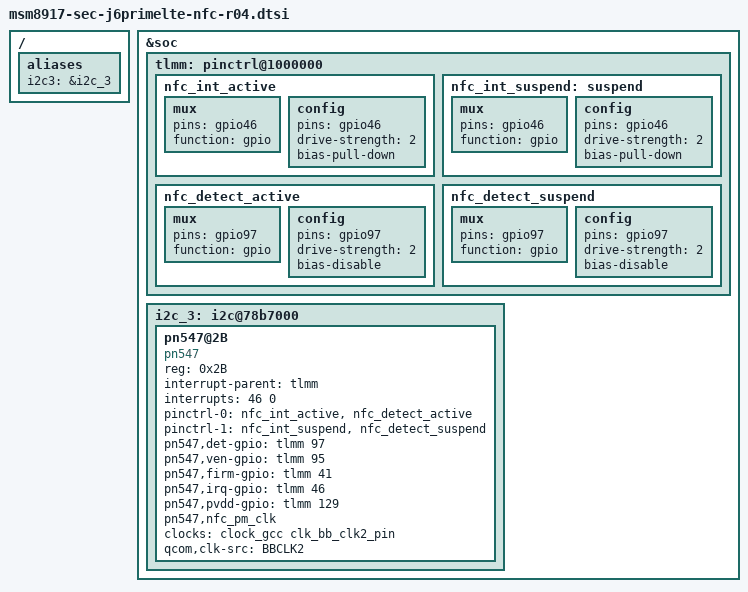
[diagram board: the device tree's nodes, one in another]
/* Copyright (c) 2017-2018, The Linux Foundation. All rights reserved.
 *
 * This program is free software; you can redistribute it and/or modify
 * it under the terms of the GNU General Public License version 2 and
 * only version 2 as published by the Free Software Foundation.
 *
 * This program is distributed in the hope that it will be useful,
 * but WITHOUT ANY WARRANTY; without even the implied warranty of
 * MERCHANTABILITY or FITNESS FOR A PARTICULAR PURPOSE.  See the
 * GNU General Public License for more details.
 */
/ {
	aliases {
		i2c3 = &i2c_3;
	};
};

&soc {
	tlmm: pinctrl@1000000 {
		/delete-node/ pmx_rd_nfc_int;

		nfc_int_active: nfc_int_active {
			mux {
				pins = "gpio46";
				function = "gpio";
			};
			config {
				pins = "gpio46";
				drive-strength = <2>;
				bias-pull-down;
			};
		};
		nfc_int_suspend: suspend  {
			mux {
				pins = "gpio46";
				function = "gpio";
			};
			config {
				pins = "gpio46";
				drive-strength = <2>;
				bias-pull-down;
			};
		};

		nfc_detect_active: nfc_detect_active {
			mux {
				pins = "gpio97";
				function = "gpio";
			};
			config {
				pins = "gpio97";
				drive-strength = <2>;
				bias-disable;		/* No PULL */
			};
		};
		nfc_detect_suspend: nfc_detect_suspend {
			mux {
				pins = "gpio97";
				function = "gpio";
			};
			config {
				pins = "gpio97";
				drive-strength = <2>;
				bias-disable;		/* No PULL */
			};
		};
	};

	i2c_3: i2c@78b7000 { /* BLSP1 QUP3 */
/*
		compatible = "qcom,i2c-msm-v2";
		#address-cells = <1>;
		#size-cells = <0>;
		reg-names = "qup_phys_addr";
		reg = <0x78b7000 0x600>;
		interrupt-names = "qup_irq";
		interrupts = <0 97 0>;
		qcom,clk-freq-out = <400000>;
		qcom,clk-freq-in  = <19200000>;
		clock-names = "iface_clk", "core_clk";
		clocks = <&clock_gcc clk_gcc_blsp1_ahb_clk>,
			<&clock_gcc clk_gcc_blsp1_qup3_i2c_apps_clk>;

		pinctrl-names = "i2c_active", "i2c_sleep";
		pinctrl-0 = <&i2c_3_active>;
		pinctrl-1 = <&i2c_3_sleep>;
		qcom,noise-rjct-scl = <0>;
		qcom,noise-rjct-sda = <0>;
		qcom,master-id = <86>;
		dmas = <&dma_blsp1 8 64 0x20000020 0x20>,
			<&dma_blsp1 9 32 0x20000020 0x20>;
		dma-names = "tx", "rx";
*/
		status = "ok";
		pn547@2B {
			compatible = "pn547";
			reg = <0x2B>;
			interrupt-parent = <&tlmm>;
			interrupts = <46 0>;
			pinctrl-names = "default", "sleep";
			pinctrl-0 = <&nfc_int_active &nfc_detect_active>;
			pinctrl-1 = <&nfc_int_suspend &nfc_detect_suspend>;
			pn547,det-gpio = <&tlmm 97 0>;
			pn547,ven-gpio = <&tlmm 95 0>;
			pn547,firm-gpio = <&tlmm 41 0>;
			pn547,irq-gpio = <&tlmm 46 0>;
			pn547,pvdd-gpio = <&tlmm 129 0>;
			pn547,nfc_pm_clk;
			clock-names = "rf_clk";
			clocks = <&clock_gcc clk_bb_clk2_pin>;
			qcom,clk-src="BBCLK2";
		};
	};
};
